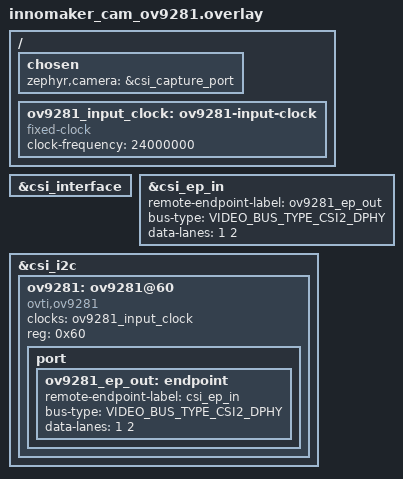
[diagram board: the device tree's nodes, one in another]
/*
 * Copyright (c) 2026 Alp Lab AB
 *
 * SPDX-License-Identifier: Apache-2.0
 *
 * InnoMaker CAM-OV9281 (OmniVision OV9281 global-shutter mono), 24 MHz
 * module oscillator, CCI address 0x60, 2 MIPI data lanes. Board-agnostic:
 * follows the upstream raspberry_pi_camera_module_2 shield's label
 * contract EXACTLY (`chosen zephyr,camera`, `&csi_interface`,
 * `&csi_ep_in`, `&csi_i2c`) -- see zephyrproject-rtos/zephyr
 * boards/shields/raspberry_pi_camera_module_2/raspberry_pi_camera_module_2.overlay
 * -- so it plugs into ANY carrier connector shield that defines those
 * labels. On alp-sdk that carrier shield is the E1M-EVK's
 * e1m_evk_rpi_csi connector shield (owned + provided separately); build
 * with SHIELD="e1m_evk_rpi_csi innomaker_cam_ov9281".
 */

#include <zephyr/dt-bindings/gpio/raspberrypi-csi-connector.h>
#include <zephyr/dt-bindings/video/video-interfaces.h>

/ {
	chosen {
		zephyr,camera = &csi_capture_port;
	};

	ov9281_input_clock: ov9281-input-clock {
		compatible = "fixed-clock";
		clock-frequency = <24000000>;
		#clock-cells = <0>;
	};
};

&csi_interface {
	status = "okay";
};

&csi_ep_in {
	remote-endpoint-label = "ov9281_ep_out";
	bus-type = <VIDEO_BUS_TYPE_CSI2_DPHY>;
	data-lanes = <1 2>;
};

&csi_i2c {
	ov9281: ov9281@60 {
		compatible = "ovti,ov9281";
		clocks = <&ov9281_input_clock>;
		reg = <0x60>;

		port {
			ov9281_ep_out: endpoint {
				remote-endpoint-label = "csi_ep_in";
				bus-type = <VIDEO_BUS_TYPE_CSI2_DPHY>;
				data-lanes = <1 2>;
			};
		};
	};
};
